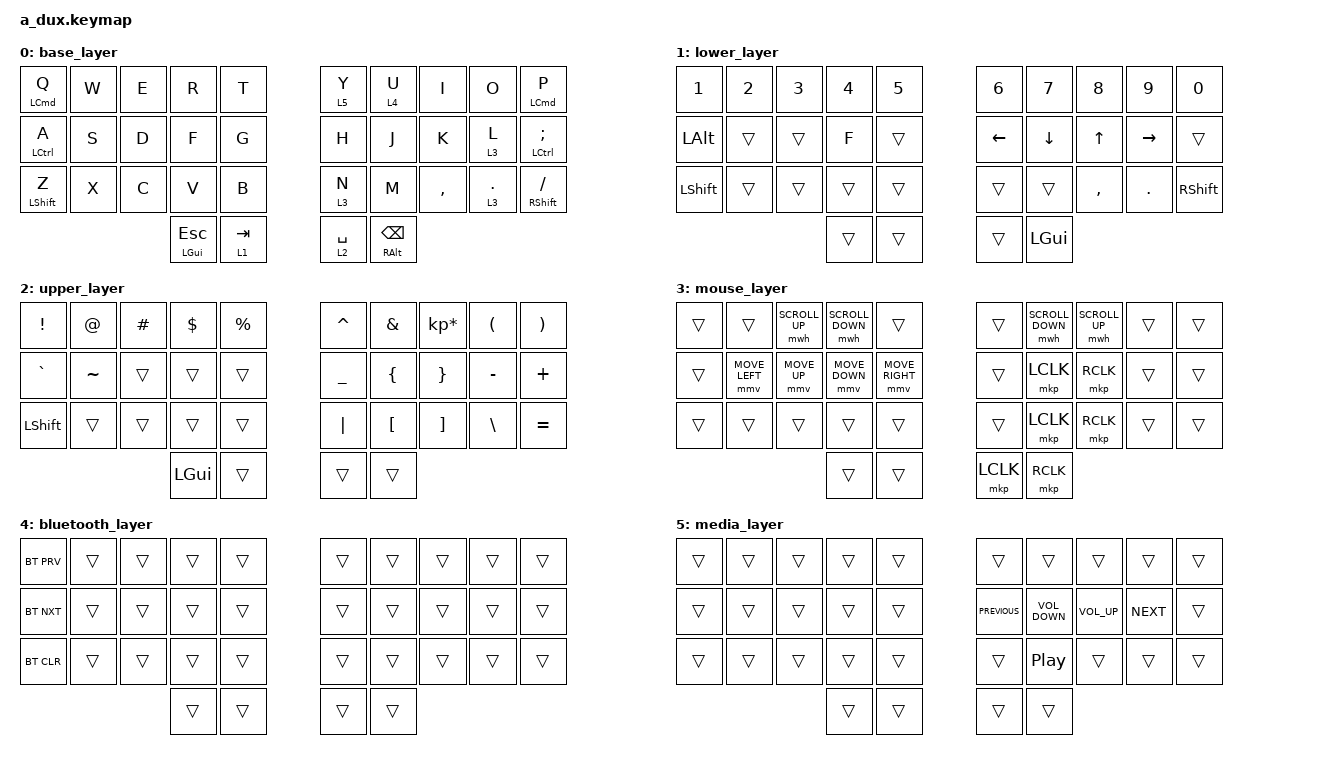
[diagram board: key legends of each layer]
/*
 * Copyright (c) 2021 The ZMK Contributors
 *
 * SPDX-License-Identifier: MIT
 */

#include <behaviors.dtsi>
#include <dt-bindings/zmk/keys.h>
#include <dt-bindings/zmk/bt.h>
#include <dt-bindings/zmk/mouse.h>

&kscan0 {
    debounce-press-ms = <24>;
    debounce-release-ms = <24>;
};

&mt {
	flavor = "balanced";
	tapping_term_ms = <125>;
	quick_tap_ms = <200>;
};

&lt {
	flavor = "balanced";
	tapping_term_ms = <125>;
	quick_tap_ms = <200>;
};

&mwh {
	delay-ms = <0>;
	time-to-max-speed-ms=<1>;
	acceleration-exponent=<1>;
};

&mmv {
	delay-ms = <0>;
	time-to-max-speed-ms=<100>;
	acceleration-exponent=<2>;
};


#define U_MOUSE_SCROLL_MAX 50
#undef SCROLL_UP
#undef SCROLL_DOWN
#define SCROLL_UP SCROLL_VERT(U_MOUSE_SCROLL_MAX)
#define SCROLL_DOWN SCROLL_VERT(-U_MOUSE_SCROLL_MAX)

#define U_MOUSE_MOVE_MAX 1000
#undef MOVE_UP
#undef MOVE_DOWN
#undef MOVE_LEFT
#undef MOVE_RIGHT
#define MOVE_UP MOVE_VERT(-U_MOUSE_MOVE_MAX)
#define MOVE_DOWN MOVE_VERT(U_MOUSE_MOVE_MAX)
#define MOVE_LEFT MOVE_HOR(-U_MOUSE_MOVE_MAX)
#define MOVE_RIGHT MOVE_HOR(U_MOUSE_MOVE_MAX)

/ {
/*
	macros {
		space_equals_space: space_equals_space {
		    label = "space_equals_space";
		    compatible = "zmk,behavior-macro";
		    #binding-cells = <0>;
		    bindings = <&macro_tap &kp SPACE &kp EQUAL &kp SPACE>;
		};
	};
*/	
	combos {
		compatible = "zmk,combos";
		combo_enter_0 {
			timeout-ms = <25>;
			key-positions = <15 16>;
			bindings = <&kp RET>;
		};
		combo_enter_1 {
			timeout-ms = <25>;
			key-positions = <25 26>;
			bindings = <&kp RET>;
		};
		combo_colon {
			timeout-ms = <25>;
			key-positions = <19 29>;
			bindings = <&kp LS(SEMI)>;
		};
/*
		combo_assignment_macro {
			timeout-ms = <25>;
			key-positions = <28 29>;
			bindings = <&space_equals_space>;
		};
*/
		// layer key symbol combos
		combo_plus {
			timeout-ms = <25>;
			key-positions = <32 19>;
			bindings = <&kp PLUS>;
		};
		combo_minus {
			timeout-ms = <25>;
			key-positions = <32 18>;
			bindings = <&kp MINUS>;
		};
		combo_underscore {
			timeout-ms = <25>;
			key-positions = <32 15>;
			bindings = <&kp UNDER>;
		};
		combo_pipe {
			timeout-ms = <25>;
			key-positions = <32 25>;
			bindings = <&kp PIPE>;
		};
		combo_backslash {
			timeout-ms = <25>;
			key-positions = <32 27>;
			bindings = <&kp BSLH>;
		};
		combo_excl {
			timeout-ms = <25>;
			key-positions = <32 0>;
			bindings = <&kp EXCL>;
		};
		combo_at {
			timeout-ms = <25>;
			key-positions = <32 1>;
			bindings = <&kp AT>;
		};
		combo_hash {
			timeout-ms = <25>;
			key-positions = <32 2>;
			bindings = <&kp HASH>;
		};
		combo_dollar {
			timeout-ms = <25>;
			key-positions = <32 3>;
			bindings = <&kp DLLR>;
		};
		combo_prcnt {
			timeout-ms = <25>;
			key-positions = <32 4>;
			bindings = <&kp PRCNT>;
		};
		combo_caret {
			timeout-ms = <25>;
			key-positions = <32 5>;
			bindings = <&kp CARET>;
		};
		combo_ampersand {
			timeout-ms = <25>;
			key-positions = <32 6>;
			bindings = <&kp AMPS>;
		};
		combo_multiply {
			timeout-ms = <25>;
			key-positions = <32 7>;
			bindings = <&kp KP_MULTIPLY>;
		};
		combo_round_left {
			timeout-ms = <25>;
			key-positions = <32 8>;
			bindings = <&kp LPAR>;
		};
		combo_round_right {
			timeout-ms = <25>;
			key-positions = <32 9>;
			bindings = <&kp RPAR>;
		};
		combo_round_left_alt {
			timeout-ms = <25>;
			key-positions = <6 7>;
			bindings = <&kp LPAR>;
		};
		combo_round_right_alt {
			timeout-ms = <25>;
			key-positions = <7 8>;
			bindings = <&kp RPAR>;
		};
		combo_equals {
			timeout-ms = <25>;
			key-positions = <32 29>;
			bindings = <&kp EQUAL>;
		};
		combo_equals_alt {
			timeout-ms = <25>;
			key-positions = <28 29>;
			bindings = <&kp EQUAL>;
		};
		combo_curly_left {
			timeout-ms = <25>;
			key-positions = <32 16>;
			bindings = <&kp LBRC>;
		};
		combo_curly_right {
			timeout-ms = <25>;
			key-positions = <32 17>;
			bindings = <&kp RBRC>;
		};
		combo_curly_left_left {
			timeout-ms = <25>;
			key-positions = <16 17>;
			bindings = <&kp LBRC>;
		};
		combo_curly_right_right {
			timeout-ms = <25>;
			key-positions = <17 18>;
			bindings = <&kp RBRC>;
		};
		combo_double_quote {
			timeout-ms = <25>;
			key-positions = <8 9>;
			bindings = <&kp DQT>;
		};
		combo_single_quote {
			timeout-ms = <25>;
			key-positions = <18 19>;
			bindings = <&kp SQT>;
		};
		combo_lt {
			timeout-ms = <25>;
			key-positions = <26 27>;
			bindings = <&kp LT>;
		};
		combo_gt {
			timeout-ms = <25>;
			key-positions = <27 28>;
			bindings = <&kp GT>;
		};

		//num combos
		combo_1 {
			timeout-ms = <25>;
			key-positions = <31 0>;
			bindings = <&kp N1>;
		};
		combo_2 {
			timeout-ms = <25>;
			key-positions = <31 1>;
			bindings = <&kp N2>;
		};
		combo_3 {
			timeout-ms = <25>;
			key-positions = <31 2>;
			bindings = <&kp N3>;
		};
		combo_4 {
			timeout-ms = <25>;
			key-positions = <31 3>;
			bindings = <&kp N4>;
		};
		combo_5 {
			timeout-ms = <25>;
			key-positions = <31 4>;
			bindings = <&kp N5>;
		};
		combo_6 {
			timeout-ms = <25>;
			key-positions = <31 5>;
			bindings = <&kp N6>;
		};
		combo_7 {
			timeout-ms = <25>;
			key-positions = <31 6>;
			bindings = <&kp N7>;
		};
		combo_8 {
			timeout-ms = <25>;
			key-positions = <31 7>;
			bindings = <&kp N8>;
		};
		combo_9 {
			timeout-ms = <25>;
			key-positions = <31 8>;
			bindings = <&kp N9>;
		};
		combo_0 {
			timeout-ms = <25>;
			key-positions = <31 9>;
			bindings = <&kp N0>;
		};
	};

	keymap {
		compatible = "zmk,keymap";

		base_layer {
			bindings = <
				&mt LCMD Q &kp W &kp E &kp R &kp T &lt 5 Y &lt 4 U &kp I &kp O &mt LCMD  P
				&mt LCTRL A &kp S &kp D &kp F &kp G &kp H &kp J &kp K &lt 3 L &mt LCTRL SEMI
				&mt LSHFT Z &kp X &kp C &kp V &kp B &lt 3 N &kp M &kp COMMA &lt 3 DOT &mt RSHFT FSLH 
				&mt LGUI ESC &lt 1 TAB &lt 2 SPACE &mt RALT BSPC
				>;
		};

		lower_layer {
			bindings = <
				&kp N1 &kp N2 &kp N3 &kp N4 &kp N5 &kp N6 &kp N7 &kp N8 &kp N9 &kp N0
				&kp LALT &trans &trans &kp F &trans &kp LEFT &kp DOWN &kp UP &kp RIGHT &trans
				&kp LSHFT &trans &trans &trans &trans &trans &trans &kp COMMA &kp DOT &kp RSHFT
				&trans &trans &trans &kp LGUI
				>;
		};

		upper_layer {
			bindings = <
				&kp EXCL &kp AT &kp HASH &kp DLLR &kp PRCNT &kp CARET &kp AMPS &kp KP_MULTIPLY &kp LPAR &kp RPAR
				&kp GRAVE &kp TILDE &trans &trans &trans &kp UNDER &kp LBRC &kp RBRC &kp MINUS &kp PLUS
				&kp LSHFT &trans &trans &trans &trans &kp PIPE &kp LBKT &kp RBKT &kp BSLH &kp EQUAL
				&kp LGUI &trans &trans &trans
				>;
		};

		mouse_layer {
			bindings = <
				&trans &trans &mwh SCROLL_UP &mwh SCROLL_DOWN &trans &trans &mwh SCROLL_DOWN &mwh SCROLL_UP &trans &trans 
				&trans &mmv MOVE_LEFT &mmv MOVE_UP &mmv MOVE_DOWN &mmv MOVE_RIGHT &trans &mkp LCLK &mkp RCLK &trans &trans 
				&trans &trans &trans &trans &trans &trans &mkp LCLK &mkp RCLK &trans &trans 
				&trans &trans &mkp LCLK &mkp RCLK
				>;
		};

		bluetooth_layer {
			bindings = <
				&bt BT_PRV &trans &trans &trans &trans &trans &trans &trans &trans &trans 
				&bt BT_NXT &trans &trans &trans &trans &trans &trans &trans &trans &trans 
				&bt BT_CLR &trans &trans &trans &trans &trans &trans &trans &trans &trans 
				&trans &trans &trans &trans
				>;
		};

		media_layer {
			bindings = <
				&trans &trans &trans &trans &trans &trans &trans &trans &trans &trans 
				&trans &trans &trans &trans &trans &kp C_PREVIOUS &kp C_VOLUME_DOWN &kp C_VOLUME_UP &kp C_NEXT &trans 
				&trans &trans &trans &trans &trans &trans &kp C_PLAY_PAUSE &trans &trans &trans 
				&trans &trans &trans &trans
				>;
		};
	};
};
